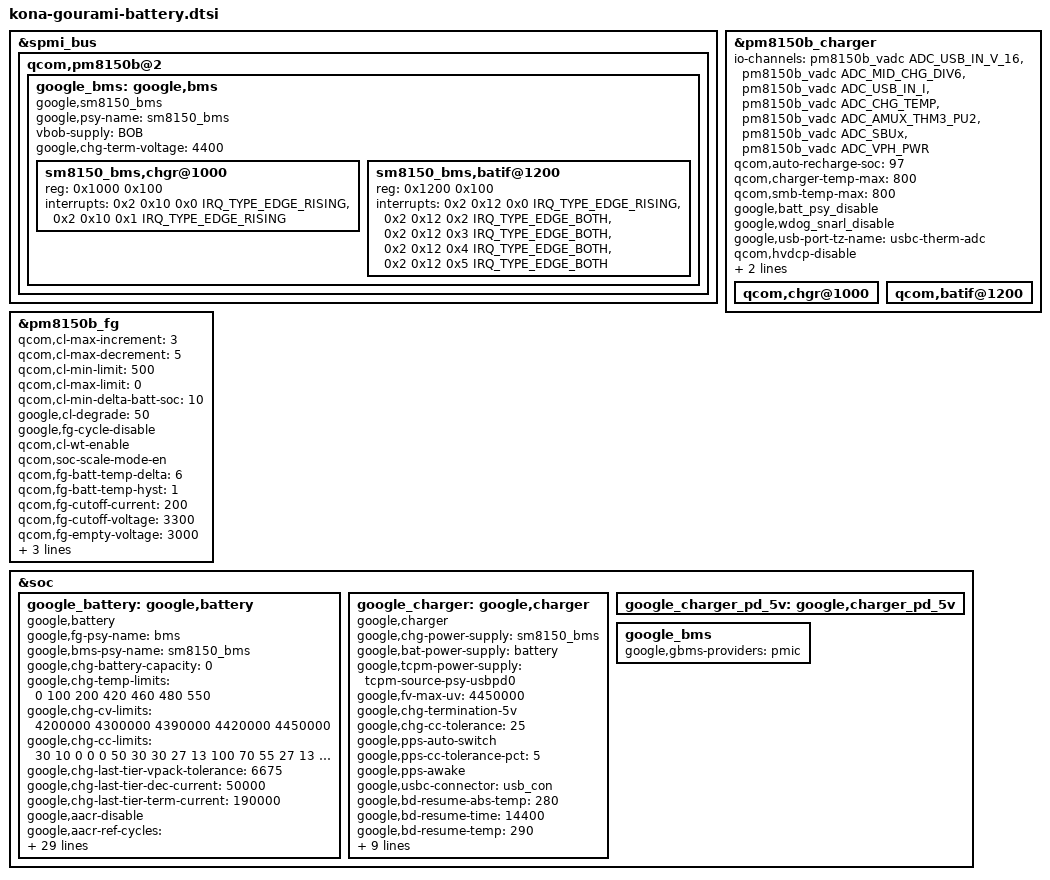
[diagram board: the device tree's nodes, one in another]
// SPDX-License-Identifier: GPL-2.0
/* Copyright (c) 2022, The Linux Foundation. All rights reserved.
 *
 * This program is free software; you can redistribute it and/or modify
 * it under the terms of the GNU General Public License version 2 and
 * only version 2 as published by the Free Software Foundation.
 *
 * This program is distributed in the hope that it will be useful,
 * but WITHOUT ANY WARRANTY; without even the implied warranty of
 * MERCHANTABILITY or FITNESS FOR A PARTICULAR PURPOSE.  See the
 * GNU General Public License for more details.
 */

&spmi_bus {
	qcom,pm8150b@2 {
		google_bms: google,bms {
			compatible = "google,sm8150_bms";
			google,psy-name = "sm8150_bms";
			vbob-supply = <&BOB>;

			google,chg-term-voltage = <4400>;

			sm8150_bms,chgr@1000 {
				reg = <0x1000 0x100>;
				interrupts =
					<0x2 0x10 0x0 IRQ_TYPE_EDGE_RISING>,
					<0x2 0x10 0x1 IRQ_TYPE_EDGE_RISING>;
				interrupt-names =
					"chgr-error",
					"chg-state-change";
			};

			sm8150_bms,batif@1200 {
				reg = <0x1200 0x100>;
				interrupts =
					<0x2 0x12 0x0 IRQ_TYPE_EDGE_RISING>,
					<0x2 0x12 0x2 IRQ_TYPE_EDGE_BOTH>,
					<0x2 0x12 0x3 IRQ_TYPE_EDGE_BOTH>,
					<0x2 0x12 0x4 IRQ_TYPE_EDGE_BOTH>,
					<0x2 0x12 0x5 IRQ_TYPE_EDGE_BOTH>;

				interrupt-names = "bat-temp",
						  "bat-ov",
						  "bat-low",
						  "bat-therm-or-id-missing",
						  "bat-terminal-missing";
			};
		};
	};
};

&pm8150b_charger {
	io-channels = <&pm8150b_vadc ADC_USB_IN_V_16>,
		      <&pm8150b_vadc ADC_MID_CHG_DIV6>,
		      <&pm8150b_vadc ADC_USB_IN_I>,
		      <&pm8150b_vadc ADC_CHG_TEMP>,
		      <&pm8150b_vadc ADC_AMUX_THM3_PU2>,
		      <&pm8150b_vadc ADC_SBUx>,
		      <&pm8150b_vadc ADC_VPH_PWR>;
	io-channel-names = "usb_in_voltage",
			   "mid_voltage",
			   "usb_in_current",
			   "chg_temp",
			   "conn_temp",
			   "sbux_res",
			   "vph_voltage";
	qcom,auto-recharge-soc = <97>;
	qcom,charger-temp-max = <800>;
	qcom,smb-temp-max = <800>;
	google,batt_psy_disable;
	google,wdog_snarl_disable;
	google,usb-port-tz-name = "usbc-therm-adc";
	qcom,hvdcp-disable;
	qcom,chg-term-src = <1>;
	qcom,disable-suspend-on-collapse;

	qcom,chgr@1000 {
		/delete-property/ interrupts;
		/delete-property/ interrupt-names;
	};

	qcom,batif@1200 {
		/delete-property/ interrupts;
		/delete-property/ interrupt-names;
	};
};

&pm8150b_fg {
	qcom,cl-max-increment = <3>;
	qcom,cl-max-decrement = <5>;
	qcom,cl-min-limit = <500>;
	qcom,cl-max-limit = <0>;
	qcom,cl-min-delta-batt-soc = <10>;
	google,cl-degrade = <50>;
	google,fg-cycle-disable;
	qcom,cl-wt-enable;
	qcom,soc-scale-mode-en;
	qcom,fg-batt-temp-delta = <6>;
	qcom,fg-batt-temp-hyst = <1>;
	qcom,fg-cutoff-current = <200>;
	qcom,fg-cutoff-voltage = <3300>;
	qcom,fg-empty-voltage = <3000>;
	qcom,fg-sys-term-current = <(-580)>;
	qcom,five-pin-battery;

	qcom,fg-force-load-profile;
};

&soc {
	google_battery: google,battery {
		compatible = "google,battery";
		google,fg-psy-name = "bms";
		google,bms-psy-name = "sm8150_bms";

		/* chg-battery-capacity = <0> -> read FULL_DESIGN from FG */
		google,chg-battery-capacity = <0>;

		/* charge table for gourami */
		google,chg-temp-limits = <0 100 200 420 460 480 550>;
		google,chg-cv-limits = <4200000 4300000 4390000 4420000 4450000>;
		google,chg-cc-limits = <
		 	30  10   0   0   0
		 	50  30  30  27  13
			100  70  55  27  13
		 	80  50  50  27  13
		 	50  50   0   0   0
			30   0   0   0   0
		>;
		/* micro-adjust cc_max to avoid vpack exceeding spec criteria */
		/* vpack tolerance: 6675uV = 4450mV * 15 / (10 * 1000) */
		google,chg-last-tier-vpack-tolerance = <6675>;
		/* decrease and terminal current unit : uA */
		google,chg-last-tier-dec-current = <50000>;
		google,chg-last-tier-term-current = <190000>;

		google,aacr-disable;
		google,aacr-ref-cycles = <300 400 500 600 700 800>;
		google,aacr-ref-fade10 = <2  14  26  36  45  54>;

		/* battery poll rate */
		google,update-interval = <30000>;
		/* IRDrop Compensation */
		google,fv-uv-resolution = <10000>;
		google,fv-uv-margin-dpct = <1025>;
		/* tier switch */
		google,cv-range-accuracy = <100000>;
		google,cv-otv-margin = <110000>;
		google,cv-debounce-cnt = <3>;
		google,cv-tier-ov-cnt = <1>;
		google,cv-tier-switch-cnt = <3>;
		/* resistance estimation */
		google,res-temp-hi = <390>;
		google,res-temp-lo = <350>;
		google,res-soc-thresh = <75>;
		google,res-filt-length = <10>;
		/* enable cycle counts */
		google,cycle-counts;

		#thermal-sensor-cells = <0>;

		/* soc smothing */
		google,rl_delta-max-soc = <1>;
		google,rl_delta-max-time = <15>;
		google,rl_ft-low-limit = <7>;
		google,rl_ft-delta-limit = <15>;
		google,rl_st-delta-limit = <7>;
		google,rl_st-max-count = <3>;
		google,rl_no-zero;
		google,rl_soc-limits = <20 30 40 50 60 70 90 100>;
		google,rl_soc-rates =  <25 26 27 28 29 28 27 22>;
		/* rest charging */
		google,chg-rest-rate = <15>;
		google,chg-rest-soc = <80>;

		google,ssoc-delta = <2>;
		/* TRICKLE-DEFEND threshold */
		google,bd-trickle-recharge-soc = <80>;
		/* Enable TRICKLE-DEFEND */
		google,bd-trickle-enable;
	};

	google_charger: google,charger {
		compatible = "google,charger";
		#cooling-cells = <2>;
		google,chg-power-supply = "sm8150_bms";
		google,bat-power-supply = "battery";
		google,tcpm-power-supply = "tcpm-source-psy-usbpd0";
		google,fv-max-uv = <4450000>;
		google,chg-termination-5v;

		/* TODO: remove when using proper "charger" */
		google,chg-cc-tolerance = <25>;

		google,pps-auto-switch;
		google,pps-cc-tolerance-pct = <5>;
		google,pps-awake;
		google,usbc-connector = <&usb_con>;

		/* b/170700459 thresholds */
		google,bd-resume-abs-temp = <280>;
		google,bd-resume-time = <14400>;  /* 4 hours */
		google,bd-resume-temp = <290>;
		google,bd-resume-soc = <50>;
		google,bd-trigger-time = <21600>; /* 6 hours */
		google,bd-trigger-temp = <350>;
		google,bd-trigger-voltage = <4270000>;
		google,bd-recharge-voltage = <4250000>;
		google,bd-drainto-soc = <80>;
		google,bd-recharge-soc = <79>;
		/* Enable TEMP-DEFEND */
		google,bd-temp-enable;
		google,bd-temp-dry-run;
	};

	google_charger_pd_5v: google,charger_pd_5v {
		#cooling-cells = <2>;
	};

	google_bms {
		google,gbms-providers = "pmic";
	};
};
